// Create by TSMaster

VERSION ""

NS_ :

BS_:

BU_: Multiplexed

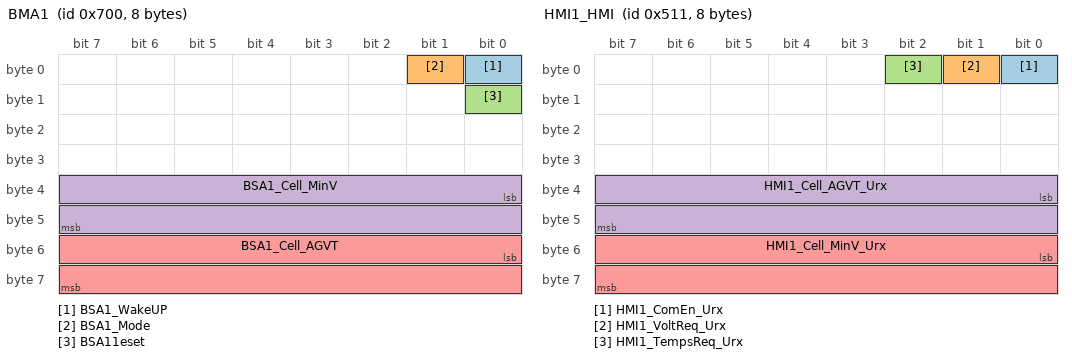
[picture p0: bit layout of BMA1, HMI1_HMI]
BO_ 1792 BMA1: 8 Vector__XXX
 SG_ BSA1_WakeUP : 0|1@1+ (1.0,0) [0.0|1.0] "" Vector__XXX
 SG_ BSA1_Mode : 1|1@1+ (1.0,0) [0.0|1.0] "" Vector__XXX
 SG_ BSA11eset : 8|1@1+ (1.0,0) [0.0|1.0] "" Vector__XXX
 SG_ BSA1_Cell_MinV : 32|16@1+ (0.001,0) [2.8|4.5] "" Vector__XXX
 SG_ BSA1_Cell_AGVT : 48|16@1- (0.1,0) [-40.0|100.0] "" Vector__XXX

BO_ 1297 HMI1_HMI: 8 Vector__XXX
 SG_ HMI1_ComEn_Urx : 0|1@1+ (1.0,0) [0.0|1.0] "" Vector__XXX
 SG_ HMI1_VoltReq_Urx : 1|1@1+ (1.0,0) [0.0|1.0] "" Vector__XXX
 SG_ HMI1_TempsReq_Urx : 2|1@1+ (1.0,0) [0.0|1.0] "" Vector__XXX
 SG_ HMI1_Cell_AGVT_Urx : 32|16@1- (0.1,0) [-40.0|100.0] "" Vector__XXX
 SG_ HMI1_Cell_MinV_Urx : 48|16@1+ (0.001,0) [2.8|4.5] "" Vector__XXX

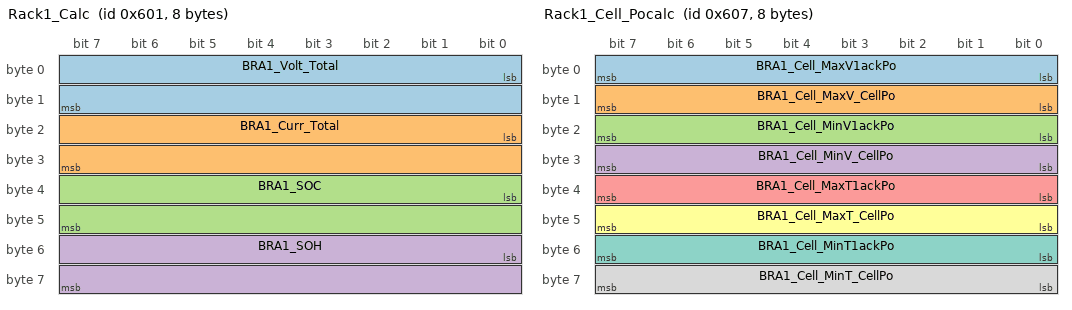
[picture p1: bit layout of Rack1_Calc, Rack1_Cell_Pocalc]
BO_ 1537 Rack1_Calc: 8 Vector__XXX
 SG_ BRA1_Volt_Total : 0|16@1+ (0.1,0) [400.0|800.0] "" Vector__XXX
 SG_ BRA1_Curr_Total : 16|16@1- (0.1,0) [-500.0|500.0] "" Vector__XXX
 SG_ BRA1_SOC : 32|16@1+ (0.1,0) [0.0|120.0] "" Vector__XXX
 SG_ BRA1_SOH : 48|16@1+ (0.1,0) [0.0|100.0] "" Vector__XXX

BO_ 1543 Rack1_Cell_Pocalc: 8 Vector__XXX
 SG_ BRA1_Cell_MaxV1ackPo : 0|8@1+ (1.0,0) [1.0|4.0] "" Vector__XXX
 SG_ BRA1_Cell_MaxV_CellPo : 8|8@1+ (1.0,0) [1.0|168.0] "" Vector__XXX
 SG_ BRA1_Cell_MinV1ackPo : 16|8@1+ (1.0,0) [1.0|4.0] "" Vector__XXX
 SG_ BRA1_Cell_MinV_CellPo : 24|8@1+ (1.0,0) [1.0|168.0] "" Vector__XXX
 SG_ BRA1_Cell_MaxT1ackPo : 32|8@1+ (1.0,0) [1.0|4.0] "" Vector__XXX
 SG_ BRA1_Cell_MaxT_CellPo : 40|8@1+ (1.0,0) [1.0|168.0] "" Vector__XXX
 SG_ BRA1_Cell_MinT1ackPo : 48|8@1+ (1.0,0) [1.0|4.0] "" Vector__XXX
 SG_ BRA1_Cell_MinT_CellPo : 56|8@1+ (1.0,0) [1.0|168.0] "" Vector__XXX

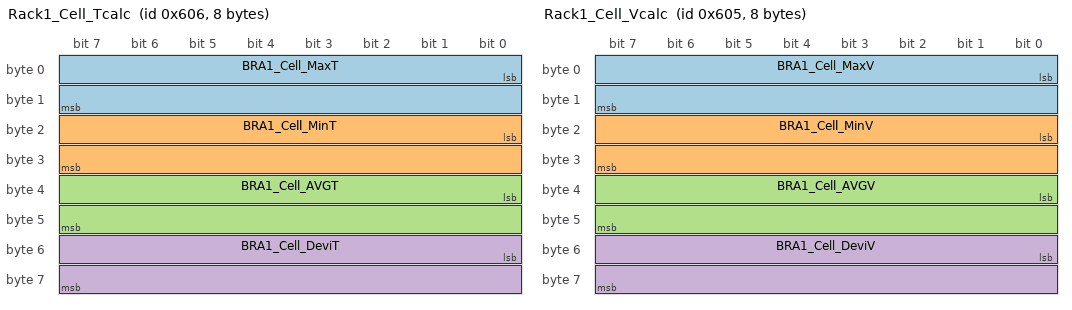
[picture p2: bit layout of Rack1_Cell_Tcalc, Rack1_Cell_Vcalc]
BO_ 1542 Rack1_Cell_Tcalc: 8 Vector__XXX
 SG_ BRA1_Cell_MaxT : 0|16@1- (0.1,0) [-40.0|100.0] "" Vector__XXX
 SG_ BRA1_Cell_MinT : 16|16@1- (0.1,0) [-40.0|100.0] "" Vector__XXX
 SG_ BRA1_Cell_AVGT : 32|16@1- (0.1,0) [-40.0|100.0] "" Vector__XXX
 SG_ BRA1_Cell_DeviT : 48|16@1+ (0.1,0) [-40.0|100.0] "" Vector__XXX

BO_ 1541 Rack1_Cell_Vcalc: 8 Vector__XXX
 SG_ BRA1_Cell_MaxV : 0|16@1+ (0.001,0) [2.8|4.5] "" Vector__XXX
 SG_ BRA1_Cell_MinV : 16|16@1+ (0.001,0) [2.8|4.5] "" Vector__XXX
 SG_ BRA1_Cell_AVGV : 32|16@1+ (0.001,0) [2.8|4.5] "" Vector__XXX
 SG_ BRA1_Cell_DeviV : 48|16@1+ (1.0,0) [0.0|500.0] "" Vector__XXX

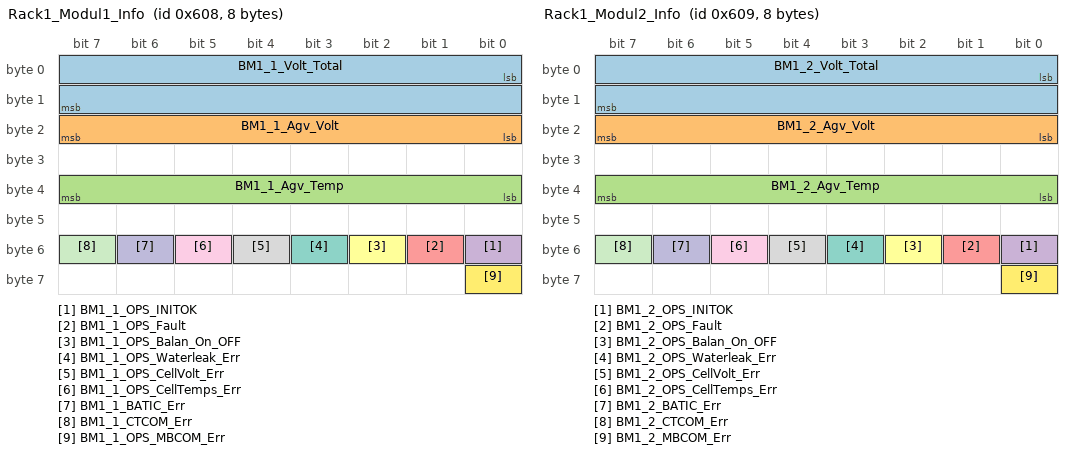
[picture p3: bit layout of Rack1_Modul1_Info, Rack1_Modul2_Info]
BO_ 1544 Rack1_Modul1_Info: 8 Vector__XXX
 SG_ BM1_1_Volt_Total : 0|16@1+ (0.1,0) [48.0|108.0] "" Vector__XXX
 SG_ BM1_1_Agv_Volt : 16|8@1+ (0.001,0) [2.8|4.5] "" Vector__XXX
 SG_ BM1_1_Agv_Temp : 32|8@1- (0.1,0) [-40.0|100.0] "" Vector__XXX
 SG_ BM1_1_OPS_INITOK : 48|1@1+ (0.0,0) [0.0|1.0] "" Vector__XXX
 SG_ BM1_1_OPS_Fault : 49|1@1+ (0.0,0) [0.0|1.0] "" Vector__XXX
 SG_ BM1_1_OPS_Balan_On_OFF : 50|1@1+ (0.0,0) [0.0|1.0] "" Vector__XXX
 SG_ BM1_1_OPS_Waterleak_Err : 51|1@1+ (0.0,0) [0.0|1.0] "" Vector__XXX
 SG_ BM1_1_OPS_CellVolt_Err : 52|1@1+ (0.0,0) [0.0|1.0] "" Vector__XXX
 SG_ BM1_1_OPS_CellTemps_Err : 53|1@1+ (0.0,0) [0.0|1.0] "" Vector__XXX
 SG_ BM1_1_BATIC_Err : 54|1@1+ (0.0,0) [0.0|1.0] "" Vector__XXX
 SG_ BM1_1_CTCOM_Err : 55|1@1+ (0.0,0) [0.0|1.0] "" Vector__XXX
 SG_ BM1_1_OPS_MBCOM_Err : 56|1@1+ (0.0,0) [0.0|1.0] "" Vector__XXX

BO_ 1545 Rack1_Modul2_Info: 8 Vector__XXX
 SG_ BM1_2_Volt_Total : 0|16@1+ (0.1,0) [48.0|108.0] "" Vector__XXX
 SG_ BM1_2_Agv_Volt : 16|8@1+ (0.001,0) [2.8|4.5] "" Vector__XXX
 SG_ BM1_2_Agv_Temp : 32|8@1- (0.1,0) [-40.0|100.0] "" Vector__XXX
 SG_ BM1_2_OPS_INITOK : 48|1@1+ (0.0,0) [0.0|1.0] "" Vector__XXX
 SG_ BM1_2_OPS_Fault : 49|1@1+ (0.0,0) [0.0|1.0] "" Vector__XXX
 SG_ BM1_2_OPS_Balan_On_OFF : 50|1@1+ (0.0,0) [0.0|1.0] "" Vector__XXX
 SG_ BM1_2_OPS_Waterleak_Err : 51|1@1+ (0.0,0) [0.0|1.0] "" Vector__XXX
 SG_ BM1_2_OPS_CellVolt_Err : 52|1@1+ (0.0,0) [0.0|1.0] "" Vector__XXX
 SG_ BM1_2_OPS_CellTemps_Err : 53|1@1+ (0.0,0) [0.0|1.0] "" Vector__XXX
 SG_ BM1_2_BATIC_Err : 54|1@1+ (0.0,0) [0.0|1.0] "" Vector__XXX
 SG_ BM1_2_CTCOM_Err : 55|1@1+ (0.0,0) [0.0|1.0] "" Vector__XXX
 SG_ BM1_2_MBCOM_Err : 56|1@1+ (0.0,0) [0.0|1.0] "" Vector__XXX

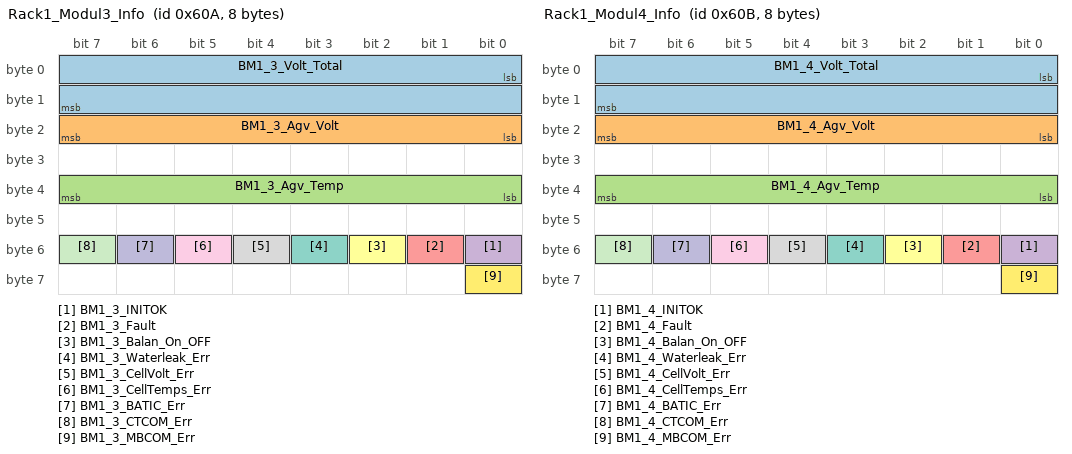
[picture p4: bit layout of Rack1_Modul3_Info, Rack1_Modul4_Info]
BO_ 1546 Rack1_Modul3_Info: 8 Vector__XXX
 SG_ BM1_3_Volt_Total : 0|16@1+ (0.1,0) [48.0|108.0] "" Vector__XXX
 SG_ BM1_3_Agv_Volt : 16|8@1+ (0.001,0) [2.8|4.5] "" Vector__XXX
 SG_ BM1_3_Agv_Temp : 32|8@1- (0.1,0) [-40.0|100.0] "" Vector__XXX
 SG_ BM1_3_INITOK : 48|1@1+ (0.0,0) [0.0|1.0] "" Vector__XXX
 SG_ BM1_3_Fault : 49|1@1+ (0.0,0) [0.0|1.0] "" Vector__XXX
 SG_ BM1_3_Balan_On_OFF : 50|1@1+ (0.0,0) [0.0|1.0] "" Vector__XXX
 SG_ BM1_3_Waterleak_Err : 51|1@1+ (0.0,0) [0.0|1.0] "" Vector__XXX
 SG_ BM1_3_CellVolt_Err : 52|1@1+ (0.0,0) [0.0|1.0] "" Vector__XXX
 SG_ BM1_3_CellTemps_Err : 53|1@1+ (0.0,0) [0.0|1.0] "" Vector__XXX
 SG_ BM1_3_BATIC_Err : 54|1@1+ (0.0,0) [0.0|1.0] "" Vector__XXX
 SG_ BM1_3_CTCOM_Err : 55|1@1+ (0.0,0) [0.0|1.0] "" Vector__XXX
 SG_ BM1_3_MBCOM_Err : 56|1@1+ (0.0,0) [0.0|1.0] "" Vector__XXX

BO_ 1547 Rack1_Modul4_Info: 8 Vector__XXX
 SG_ BM1_4_Volt_Total : 0|16@1+ (0.1,0) [48.0|108.0] "" Vector__XXX
 SG_ BM1_4_Agv_Volt : 16|8@1+ (0.001,0) [2.8|4.5] "" Vector__XXX
 SG_ BM1_4_Agv_Temp : 32|8@1- (0.1,0) [-40.0|100.0] "" Vector__XXX
 SG_ BM1_4_INITOK : 48|1@1+ (0.0,0) [0.0|1.0] "" Vector__XXX
 SG_ BM1_4_Fault : 49|1@1+ (0.0,0) [0.0|1.0] "" Vector__XXX
 SG_ BM1_4_Balan_On_OFF : 50|1@1+ (0.0,0) [0.0|1.0] "" Vector__XXX
 SG_ BM1_4_Waterleak_Err : 51|1@1+ (0.0,0) [0.0|1.0] "" Vector__XXX
 SG_ BM1_4_CellVolt_Err : 52|1@1+ (0.0,0) [0.0|1.0] "" Vector__XXX
 SG_ BM1_4_CellTemps_Err : 53|1@1+ (0.0,0) [0.0|1.0] "" Vector__XXX
 SG_ BM1_4_BATIC_Err : 54|1@1+ (0.0,0) [0.0|1.0] "" Vector__XXX
 SG_ BM1_4_CTCOM_Err : 55|1@1+ (0.0,0) [0.0|1.0] "" Vector__XXX
 SG_ BM1_4_MBCOM_Err : 56|1@1+ (0.0,0) [0.0|1.0] "" Vector__XXX

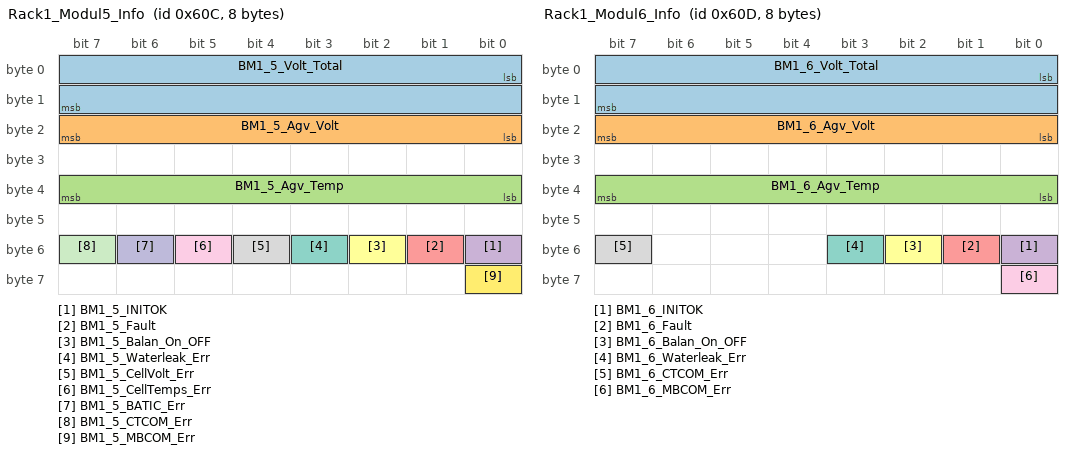
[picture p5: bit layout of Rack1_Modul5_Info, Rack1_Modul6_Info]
BO_ 1548 Rack1_Modul5_Info: 8 Vector__XXX
 SG_ BM1_5_Volt_Total : 0|16@1+ (0.1,0) [48.0|108.0] "" Vector__XXX
 SG_ BM1_5_Agv_Volt : 16|8@1+ (0.001,0) [2.8|4.5] "" Vector__XXX
 SG_ BM1_5_Agv_Temp : 32|8@1- (0.1,0) [-40.0|100.0] "" Vector__XXX
 SG_ BM1_5_INITOK : 48|1@1+ (0.0,0) [0.0|1.0] "" Vector__XXX
 SG_ BM1_5_Fault : 49|1@1+ (0.0,0) [0.0|1.0] "" Vector__XXX
 SG_ BM1_5_Balan_On_OFF : 50|1@1+ (0.0,0) [0.0|1.0] "" Vector__XXX
 SG_ BM1_5_Waterleak_Err : 51|1@1+ (0.0,0) [0.0|1.0] "" Vector__XXX
 SG_ BM1_5_CellVolt_Err : 52|1@1+ (0.0,0) [0.0|1.0] "" Vector__XXX
 SG_ BM1_5_CellTemps_Err : 53|1@1+ (0.0,0) [0.0|1.0] "" Vector__XXX
 SG_ BM1_5_BATIC_Err : 54|1@1+ (0.0,0) [0.0|1.0] "" Vector__XXX
 SG_ BM1_5_CTCOM_Err : 55|1@1+ (0.0,0) [0.0|1.0] "" Vector__XXX
 SG_ BM1_5_MBCOM_Err : 56|1@1+ (0.0,0) [0.0|1.0] "" Vector__XXX

BO_ 1549 Rack1_Modul6_Info: 8 Vector__XXX
 SG_ BM1_6_Volt_Total : 0|16@1+ (0.1,0) [48.0|108.0] "" Vector__XXX
 SG_ BM1_6_Agv_Volt : 16|8@1+ (0.001,0) [2.8|4.5] "" Vector__XXX
 SG_ BM1_6_Agv_Temp : 32|8@1- (0.1,0) [-40.0|100.0] "" Vector__XXX
 SG_ BM1_6_INITOK : 48|1@1+ (0.0,0) [0.0|1.0] "" Vector__XXX
 SG_ BM1_6_Fault : 49|1@1+ (0.0,0) [0.0|1.0] "" Vector__XXX
 SG_ BM1_6_Balan_On_OFF : 50|1@1+ (0.0,0) [0.0|1.0] "" Vector__XXX
 SG_ BM1_6_Waterleak_Err : 51|1@1+ (0.0,0) [0.0|1.0] "" Vector__XXX
 SG_ BM1_6_CTCOM_Err : 55|1@1+ (0.0,0) [0.0|1.0] "" Vector__XXX
 SG_ BM1_6_MBCOM_Err : 56|1@1+ (0.0,0) [0.0|1.0] "" Vector__XXX

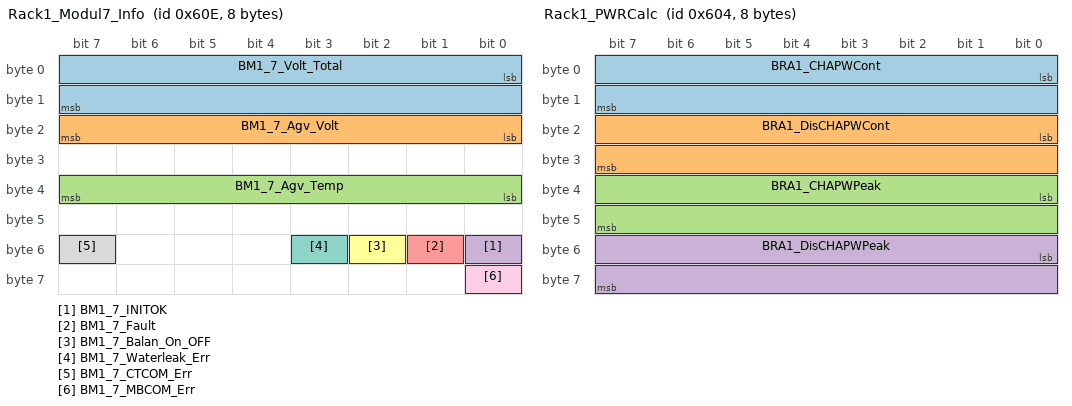
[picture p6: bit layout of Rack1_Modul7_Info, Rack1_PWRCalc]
BO_ 1550 Rack1_Modul7_Info: 8 Vector__XXX
 SG_ BM1_7_Volt_Total : 0|16@1+ (0.1,0) [48.0|108.0] "" Vector__XXX
 SG_ BM1_7_Agv_Volt : 16|8@1+ (0.001,0) [2.8|4.5] "" Vector__XXX
 SG_ BM1_7_Agv_Temp : 32|8@1- (0.1,0) [-40.0|100.0] "" Vector__XXX
 SG_ BM1_7_INITOK : 48|1@1+ (0.0,0) [0.0|1.0] "" Vector__XXX
 SG_ BM1_7_Fault : 49|1@1+ (0.0,0) [0.0|1.0] "" Vector__XXX
 SG_ BM1_7_Balan_On_OFF : 50|1@1+ (0.0,0) [0.0|1.0] "" Vector__XXX
 SG_ BM1_7_Waterleak_Err : 51|1@1+ (0.0,0) [0.0|1.0] "" Vector__XXX
 SG_ BM1_7_CTCOM_Err : 55|1@1+ (0.0,0) [0.0|1.0] "" Vector__XXX
 SG_ BM1_7_MBCOM_Err : 56|1@1+ (0.0,0) [0.0|1.0] "" Vector__XXX

BO_ 1540 Rack1_PWRCalc: 8 Vector__XXX
 SG_ BRA1_CHAPWCont : 0|16@1+ (0.1,0) [0.0|43.0] "" Vector__XXX
 SG_ BRA1_DisCHAPWCont : 16|16@1+ (0.1,0) [0.0|100.0] "" Vector__XXX
 SG_ BRA1_CHAPWPeak : 32|16@1+ (0.1,0) [0.0|60.0] "" Vector__XXX
 SG_ BRA1_DisCHAPWPeak : 48|16@1+ (0.1,0) [0.0|200.0] "" Vector__XXX

BO_ 1539 Rack1_ProtectState: 8 Vector__XXX
 SG_ BRA1_Wn_Dischager_OC : 0|1@1+ (1.0,0) [0.0|1.0] "" Vector__XXX
 SG_ BRA1_Wn_Chager_OC : 1|1@1+ (1.0,0) [0.0|1.0] "" Vector__XXX
 SG_ BRA1_Wn_SOC_OV : 2|1@1+ (1.0,0) [0.0|1.0] "" Vector__XXX
 SG_ BRA1_Wn_SOC_Un : 3|1@1+ (1.0,0) [0.0|1.0] "" Vector__XXX
 SG_ BRA1_Wn_OV : 4|1@1+ (1.0,0) [0.0|1.0] "" Vector__XXX
 SG_ BRA1_Wn_UV : 5|1@1+ (1.0,0) [0.0|1.0] "" Vector__XXX
 SG_ BRA1_Wn_Cell_OV : 6|1@1+ (1.0,0) [0.0|1.0] "" Vector__XXX
 SG_ BRA1_Wn_Cell_UV : 7|1@1+ (1.0,0) [0.0|1.0] "" Vector__XXX
 SG_ BRA1_Wn_Cell_UnbalV : 8|1@1+ (1.0,0) [0.0|1.0] "" Vector__XXX
 SG_ BRA1_Wn_DisCharger_Cell_OT : 9|1@1+ (1.0,0) [0.0|1.0] "" Vector__XXX
 SG_ BRA1_Wn_Charger_Cell_OT : 10|1@1+ (1.0,0) [0.0|1.0] "" Vector__XXX
 SG_ BRA1_Wn_DisCharger_Cell_UT : 11|1@1+ (1.0,0) [0.0|1.0] "" Vector__XXX
 SG_ BRA1_Wn_Charger_Cell_UT : 12|1@1+ (1.0,0) [0.0|1.0] "" Vector__XXX
 SG_ BRA1_Wn_Cell_UnbalT : 13|1@1+ (1.0,0) [0.0|1.0] "" Vector__XXX
 SG_ BRA1_Wn_Discharger_UnbaPWR : 14|1@1+ (1.0,0) [0.0|1.0] "" Vector__XXX
 SG_ BRA1_Wn_Charger_UnbaPWR : 15|1@1+ (1.0,0) [0.0|1.0] "" Vector__XXX
 SG_ BRA1_FLT_Dischager_OC : 16|1@1+ (1.0,0) [0.0|1.0] "" Vector__XXX
 SG_ BRA1_FLT_Chager_OC : 17|1@1+ (1.0,0) [0.0|1.0] "" Vector__XXX
 SG_ BRA1_FLT_SOC_OV : 18|1@1+ (1.0,0) [0.0|1.0] "" Vector__XXX
 SG_ BRA1_FLT_SOC_Un : 19|1@1+ (1.0,0) [0.0|1.0] "" Vector__XXX
 SG_ BRA1_FLT_OV : 20|1@1+ (1.0,0) [0.0|1.0] "" Vector__XXX
 SG_ BRA1_FLT_UV : 21|1@1+ (1.0,0) [0.0|1.0] "" Vector__XXX
 SG_ BRA1_FLT_Cell_OV : 22|1@1+ (1.0,0) [0.0|1.0] "" Vector__XXX
 SG_ BRA1_FLT_Cell_UV : 23|1@1+ (1.0,0) [0.0|1.0] "" Vector__XXX
 SG_ BRA1_FLT_Cell_UnbalV : 24|1@1+ (1.0,0) [0.0|1.0] "" Vector__XXX
 SG_ BRA1_FLT_DisCharger_Cell_OT : 25|1@1+ (1.0,0) [0.0|1.0] "" Vector__XXX
 SG_ BRA1_FLT_Charger_Cell_OT : 26|1@1+ (1.0,0) [0.0|1.0] "" Vector__XXX
 SG_ BRA1_FLT_DisCharger_Cell_UT : 27|1@1+ (1.0,0) [0.0|1.0] "" Vector__XXX
 SG_ BRA1_FLT_Charger_Cell_UT : 28|1@1+ (1.0,0) [0.0|1.0] "" Vector__XXX
 SG_ BRA1_FLT_Cell_UnbalT : 29|1@1+ (1.0,0) [0.0|1.0] "" Vector__XXX
 SG_ BRA1_FLT_Discharger_UnbaPWR : 30|1@1+ (1.0,0) [0.0|1.0] "" Vector__XXX
 SG_ BRA1_FLT_Charger_UnbaPWR : 31|1@1+ (1.0,0) [0.0|1.0] "" Vector__XXX
 SG_ BRA1_Prtct_Dischager_OC : 32|1@1+ (1.0,0) [0.0|1.0] "" Vector__XXX
 SG_ BRA1_Prtct_Chager_OC : 33|1@1+ (1.0,0) [0.0|1.0] "" Vector__XXX
 SG_ BRA1_Prtct_SOC_OV : 34|1@1+ (1.0,0) [0.0|1.0] "" Vector__XXX
 SG_ BRA1_Prtct_SOC_Un : 35|1@1+ (1.0,0) [0.0|1.0] "" Vector__XXX
 SG_ BRA1_Prtct_OV : 36|1@1+ (1.0,0) [0.0|1.0] "" Vector__XXX
 SG_ BRA1_Prtct_UV : 37|1@1+ (1.0,0) [0.0|1.0] "" Vector__XXX
 SG_ BRA1_Prtct_Cell_OV : 38|1@1+ (1.0,0) [0.0|1.0] "" Vector__XXX
 SG_ BRA1_Prtct_Cell_UV : 39|1@1+ (1.0,0) [0.0|1.0] "" Vector__XXX
 SG_ BRA1_Prtct_Cell_UnbalV : 40|1@1+ (1.0,0) [0.0|1.0] "" Vector__XXX
 SG_ BRA1_Prtct_DisCharger_Cell_OT : 41|1@1+ (1.0,0) [0.0|1.0] "" Vector__XXX
 SG_ BRA1_Prtct_Charger_Cell_OT : 42|1@1+ (1.0,0) [0.0|1.0] "" Vector__XXX
 SG_ BRA1_Prtct_DisCharger_Cell_UT : 43|1@1+ (1.0,0) [0.0|1.0] "" Vector__XXX
 SG_ BRA1_Prtct_Charger_Cell_UT : 44|1@1+ (1.0,0) [0.0|1.0] "" Vector__XXX
 SG_ BRA1_Prtct_Cell_UnbalT : 45|1@1+ (1.0,0) [0.0|1.0] "" Vector__XXX
 SG_ BRA1_Prtct_Discharger_UnbaPWR : 46|1@1+ (1.0,0) [0.0|1.0] "" Vector__XXX
 SG_ BRA1_Prtct_Charger_UnbaPWR : 47|1@1+ (1.0,0) [0.0|1.0] "" Vector__XXX
 SG_ BRA1_Prtct1ly_Err : 48|1@1+ (1.0,0) [0.0|1.0] "" Vector__XXX
 SG_ BRA1_Prtct_IN_COM_Err : 49|1@1+ (1.0,0) [0.0|1.0] "" Vector__XXX
 SG_ BRA1_Prtct_EX_COM_Err : 50|1@1+ (1.0,0) [0.0|1.0] "" Vector__XXX
 SG_ BRA1_Prtct_CT_COM_Err : 51|1@1+ (1.0,0) [0.0|1.0] "" Vector__XXX
 SG_ BRA1_Prtct_Water_Leak_Err : 52|1@1+ (1.0,0) [0.0|1.0] "" Vector__XXX
 SG_ BRA1_Prtct_EMS_SW_Err : 53|1@1+ (1.0,0) [0.0|1.0] "" Vector__XXX

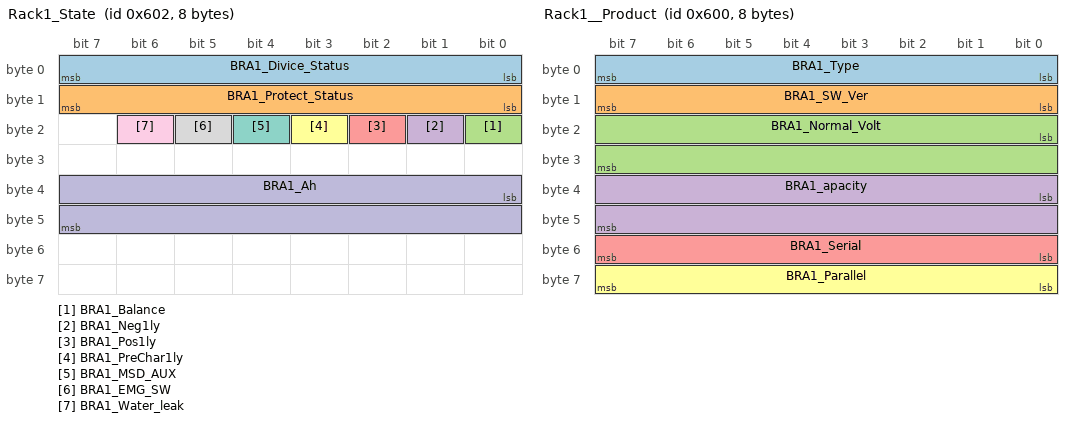
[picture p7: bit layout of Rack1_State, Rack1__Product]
BO_ 1538 Rack1_State: 8 Vector__XXX
 SG_ BRA1_Divice_Status : 0|8@1+ (1.0,0) [0.0|4.0] "" Vector__XXX
 SG_ BRA1_Protect_Status : 8|8@1+ (1.0,0) [0.0|4.0] "" Vector__XXX
 SG_ BRA1_Balance : 16|1@1+ (1.0,0) [0.0|1.0] "" Vector__XXX
 SG_ BRA1_Neg1ly : 17|1@1+ (1.0,0) [0.0|1.0] "" Vector__XXX
 SG_ BRA1_Pos1ly : 18|1@1+ (1.0,0) [0.0|1.0] "" Vector__XXX
 SG_ BRA1_PreChar1ly : 19|1@1+ (1.0,0) [0.0|1.0] "" Vector__XXX
 SG_ BRA1_MSD_AUX : 20|1@1+ (1.0,0) [0.0|1.0] "" Vector__XXX
 SG_ BRA1_EMG_SW : 21|1@1+ (1.0,0) [0.0|1.0] "" Vector__XXX
 SG_ BRA1_Water_leak : 22|1@1+ (1.0,0) [0.0|1.0] "" Vector__XXX
 SG_ BRA1_Ah : 32|16@1- (1.0,0) [-100.0|-100.0] "" Vector__XXX

BO_ 1296 Rack1_Unit: 8 Vector__XXX
 SG_ BRA1_Status_Urx : 3|0@1+ (1.0,0) [0.0|1.0] "" Vector__XXX
 SG_ BRA1_ComEn_Urx : 8|1@1+ (1.0,0) [0.0|1.0] "" Vector__XXX
 SG_ BRA11eset_Urx : 9|1@1+ (1.0,0) [0.0|1.0] "" Vector__XXX
 SG_ BRA1_Cell_AGVT_Urx : 32|16@1- (0.1,0) [-40.0|100.0] "" Vector__XXX
 SG_ BRA1_Cell_MinV_Urx : 48|16@1+ (0.001,0) [2.8|4.5] "" Vector__XXX

BO_ 1536 Rack1__Product: 8 Vector__XXX
 SG_ BRA1_Type : 0|8@1+ (1.0,0) [0.0|10.0] "" Vector__XXX
 SG_ BRA1_SW_Ver : 8|8@1+ (0.1,0) [1.0|2.55] "" Vector__XXX
 SG_ BRA1_Normal_Volt : 16|16@1+ (0.1,0) [400.0|800.0] "" Vector__XXX
 SG_ BRA1_apacity : 32|16@1+ (0.1,0) [30.0|500.0] "" Vector__XXX
 SG_ BRA1_Serial : 48|8@1+ (1.0,0) [0.0|200.0] "" Vector__XXX
 SG_ BRA1_Parallel : 56|8@1+ (1.0,0) [0.0|10.0] "" Vector__XXX

BO_ 1551 Debugg: 8 Vector__XXX
 SG_ RackRx_WakeUp : 0|1@1+ (1,0) [0|1] "F" Vector__XXX
 SG_ RackRx_ReSet : 8|1@1+ (1,0) [0|1] "F" Vector__XXX
